# HR_C7000_DM32 register map
Vendor: Dahua Technology (chip); Baofeng (radio product); Series: HR_C7000; File version: 0.1-dm32re-draft
CPU: other r0p0, little endian, no MPU, no FPU, 0 interrupt priority bits
Registers are 32-bit, read-write, reset 0x0 unless marked. A register's access mark holds for its fields unless they carry their own. Offsets are from the block's base; [hi:lo] are bit positions; 'fields as' and 'values as' point back to an identical list.

## PWM — PWM, three channels at a 0x20 stride plus a shared interrupt status at 0xff0 (DS §5.8, p.385-400). FW: the base is built arithmetically (at 0x0301c1bc), which a literal/movih sweep cannot see; channel 0 drives the LCD backlight at 1 kHz with seven duty levels.
Base 0x140C0000
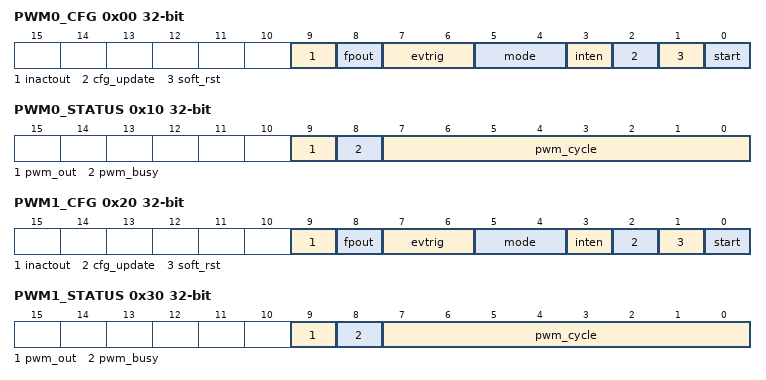
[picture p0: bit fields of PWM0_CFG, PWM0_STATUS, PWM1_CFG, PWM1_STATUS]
0x00 PWM0_CFG — PWM0 Configuration registers. DS §5.8.5.1 p.391. Reset 0x0 (DS).
  [9] inactout — pwm The output level when not enabled. [reset 0x0] [access RW]
  [8] fpout — pwm Output level of the first phase in one cycle [reset 0x0] [access RW]
  [7:6] evtrig — In ONE_SHOT Event trigger mode in mode 1: rising edge trigger 2: Falling edge trigger 0,3: Normal mode, that is, not PWM according to external signals Signal output [reset 0x0] [access RW]
  [5:4] mode — PWM Mode, 1:ONE_SHOT model 2: CONTINUOUS model 0,3: Reserved, no PWM Waveform output [reset 0x0] [access RW]
  [3] inten — Interrupt enable [reset 0x0] [access RW]
  [2] cfg_update — In CONTINUOUS mode, changes to PWM_PER and PWM_FP take effect mid-stream: after writing them, write cfg_update 0->1 so both registers update simultaneously (printed text is broken across words on p.391) [reset 0x0] [access RW]
  [1] soft_rst — Software reset enable, used to turn off PWM at any time Waveform input out. [reset 0x0] [access RW]
  [0] start — pwm Start encoding, rising edge is valid ( ie from 0 Change to 1) . [reset 0x0] [access RW]
0x04 PWM0_RPT — PWM0 ONE_SHOT Number of. DS §5.8.5.2 p.392. Reset 0x0 (DS).
  [15:0] pwm_rpt — ONE_SHOT mode: number of times the waveform is repeated [reset 0x0] [access RW]
0x08 PWM0_PER — PWM0 The periodic waveform lasts for. DS §5.8.5.3 p.393. Reset 0x0 (DS).
  [31:0] pwm_per — Length of one waveform period, in system-clock cycles [reset 0x0] [access RW]
0x0C PWM0_FP — PWM0 The number of beats that the. DS §5.8.5.4 p.393. Reset 0x0 (DS).
  [31:0] pwm_fp — Length of the first phase of each period, in system-clock cycles; if pwm_fp > pwm_per the whole period is at fpout [reset 0x0] [access RW]
0x10 PWM0_STATUS — PWM0 Status Register. DS §5.8.5.5 p.393. Reset 0x0 (DS).
  [9] pwm_out — pwm Current value of the waveform [reset 0x0] [access RW]
  [8] pwm_busy — PWM state machine: 0 idle; 1 working [reset 0x0] [access RW]
  [7:0] pwm_cycle — In CONTINUOUS mode, number of cycles output with the same pwm_per/pwm_fp parameters [reset 0x0] [access RW]
0x20 PWM1_CFG — PWM1 Configuration registers. DS §5.8.5.6 p.393. Reset 0x0 (DS).
  [9] inactout — pwm The output level when not enabled. [reset 0x0] [access RW]
  [8] fpout — pwm Output level of the first phase in one cycle [reset 0x0] [access RW]
  [7:6] evtrig — In ONE_SHOT Event trigger mode in mode 1: rising edge trigger 2: Falling edge trigger 0,3: Normal mode, that is, not PWM according to external signals Signal input out [reset 0x0] [access RW]
  [5:4] mode — PWM Mode, 1:ONE_SHOT model 2: CONTINUOUS model 0,3: Reserved, no PWM Waveform output [reset 0x0] [access RW]
  [3] inten — Interrupt enable [reset 0x0] [access RW]
  [2] cfg_update — In CONTINUOUS mode, changes to PWM_PER and PWM_FP take effect mid-stream: after writing them, write cfg_update 0->1 so both registers update simultaneously (printed text is broken across words on p.391) [reset 0x0] [access RW]
  [1] soft_rst — Software reset enable, used to turn off PWM at any time Waveform input out. [reset 0x0] [access RW]
  [0] start — pwm Start encoding, rising edge is valid ( ie from 0 Change to 1) . [reset 0x0] [access RW]
0x24 PWM1_RPT — PWM1 ONE_SHOT Number of. DS §5.8.5.7 p.395. Reset 0x0 (DS).
  fields as PWM0_RPT
0x28 PWM1_PER — PWM1 The periodic waveform lasts for. DS §5.8.5.8 p.395. Reset 0x0 (DS).
  fields as PWM0_PER
0x2C PWM1_FP — PWM1 The number of beats that the. DS §5.8.5.9 p.395. Reset 0x0 (DS).
  fields as PWM0_FP
0x30 PWM1_STATUS — PWM1 Status Register. DS §5.8.5.10 p.396. Reset 0x0 (DS).
  fields as PWM0_STATUS
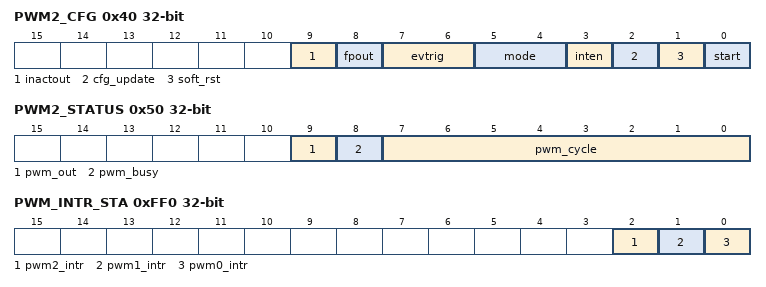
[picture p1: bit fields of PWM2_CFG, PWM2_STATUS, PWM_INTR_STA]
0x40 PWM2_CFG — PWM2 Configuration registers. DS §5.8.5.11 p.397. Reset 0x0 (DS).
  fields as PWM0_CFG
0x44 PWM2_RPT — PWM2 ONE_SHOT Number of. DS §5.8.5.12 p.397. Reset 0x0 (DS).
  [15:0] pwm_rpt — ONE_SHOT mode: number of times the waveform is repeated (printed in Chinese: 一次 ONE_SHOT 传输重复的周期数) [reset 0x0] [access RW]
0x48 PWM2_PER — PWM2 The periodic waveform lasts for. DS §5.8.5.13 p.399. Reset 0x0 (DS).
  fields as PWM0_PER
0x4C PWM2_FP — PWM2 The number of beats that the. DS §5.8.5.14 p.399. Reset 0x0 (DS).
  fields as PWM0_FP
0x50 PWM2_STATUS — PWM2 Status Register. DS §5.8.5.15 p.399. Reset 0x0 (DS).
  fields as PWM0_STATUS
0xFF0 PWM_INTR_STA ro — DS §5.8.5.16 p.399. Reset 0x0 (DS).
  [2] pwm2_intr — PWM2 output interrupt status [reset 0x0] [access RO]
  [1] pwm1_intr — PWM1 output interrupt status [reset 0x0] [access RO]
  [0] pwm0_intr — pwm0 output interrupt status [reset 0x0] [access RO]
